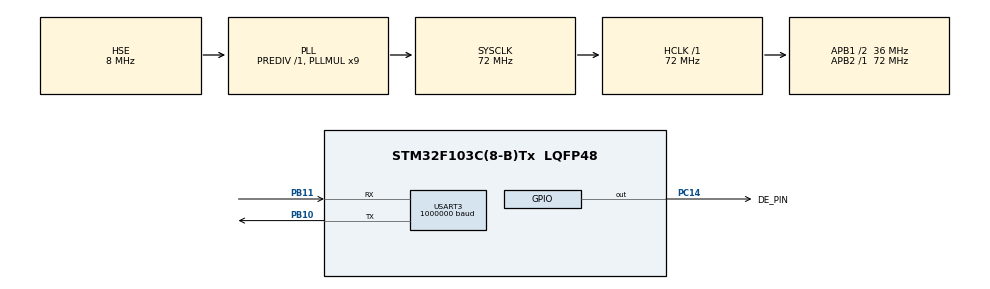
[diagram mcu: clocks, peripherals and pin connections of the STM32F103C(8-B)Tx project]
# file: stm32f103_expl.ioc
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FREERTOS.HEAP_NUMBER=4
FREERTOS.Tasks01=defaultTask,0,128,StartDefaultTask,Default,NULL
FREERTOS.configTOTAL_HEAP_SIZE=10000
Mcu.Family=STM32F1
Mcu.Name=STM32F103C(8-B)Tx
Mcu.Package=LQFP48
NVIC.PriorityGroup=NVIC_PRIORITYGROUP_4
NVIC.USART3_IRQn=true\:5\:0\:false\:false\:true\:true\:true\:true
PA13.Mode=JTAG_4_pins
PA13.Signal=SYS_JTMS-SWDIO
PA14.Mode=JTAG_4_pins
PA14.Signal=SYS_JTCK-SWCLK
PA15.Mode=JTAG_4_pins
PA15.Signal=SYS_JTDI
PB10.Mode=Asynchronous
PB10.Signal=USART3_TX
PB11.Mode=Asynchronous
PB11.Signal=USART3_RX
PB3.Mode=JTAG_4_pins
PB3.Signal=SYS_JTDO-TRACESWO
PC14-OSC32_IN.GPIO_Label=DE_PIN
PC14-OSC32_IN.Signal=GPIO_Output
PD0-OSC_IN.Mode=HSE-External-Oscillator
PD0-OSC_IN.Signal=RCC_OSC_IN
PD1-OSC_OUT.Mode=HSE-External-Oscillator
PD1-OSC_OUT.Signal=RCC_OSC_OUT
ProjectManager.HeapSize=0x200
ProjectManager.StackSize=0x400
ProjectManager.TargetToolchain=SW4STM32
RCC.AHBFreq_Value=72000000
RCC.APB1CLKDivider=RCC_HCLK_DIV2
RCC.APB1Freq_Value=36000000
RCC.APB1TimFreq_Value=72000000
RCC.APB2Freq_Value=72000000
RCC.APB2TimFreq_Value=72000000
RCC.HCLKFreq_Value=72000000
RCC.PLLMUL=RCC_PLL_MUL9
RCC.PLLSourceVirtual=RCC_PLLSOURCE_HSE
RCC.SYSCLKFreq_VALUE=72000000
RCC.SYSCLKSource=RCC_SYSCLKSOURCE_PLLCLK
RCC.USBFreq_Value=72000000
USART3.BaudRate=1000000
USART3.VirtualMode=VM_ASYNC
VP_FREERTOS_VS_CMSIS_V1.Mode=CMSIS_V1
board=custom

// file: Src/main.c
/* USER CODE BEGIN Header */
/**
  ******************************************************************************
  * @file           : main.c
  * @brief          : Main program body
  ******************************************************************************
  * @attention
  *
  * <h2><center>&copy; Copyright (c) 2019 STMicroelectronics.
  * All rights reserved.</center></h2>
  *
  * This software component is licensed by ST under BSD 3-Clause license,
  * the "License"; You may not use this file except in compliance with the
  * License. You may obtain a copy of the License at:
  *                        opensource.org/licenses/BSD-3-Clause
  *
  ******************************************************************************
  */
/* USER CODE END Header */

#include "main.h"
#include "cmsis_os.h"

/* USER CODE BEGIN Includes */
#include "ax12a.h"
/* USER CODE END Includes */

UART_HandleTypeDef huart3;

osThreadId defaultTaskHandle;

void SystemClock_Config(void);
static void MX_GPIO_Init(void);
static void MX_USART3_UART_Init(void);
void StartDefaultTask(void const * argument);

/* USER CODE BEGIN PFP */

uint8_t  packet[9];

int move(unsigned char ID, int Position) {
    char Position_H,Position_L;
    Position_H = Position >> 8;           // 16 bits - 2 x 8 bits variables
    Position_L = Position;

    const unsigned int length = 9;

    unsigned char Checksum = (~(ID + AX_GOAL_LENGTH + AX_WRITE_DATA + AX_GOAL_POSITION_L + Position_L + Position_H)) & 0xFF;

    packet[0] = AX_START;
    packet[1] = AX_START;
    packet[2] = ID;
    packet[3] = AX_GOAL_LENGTH;
    packet[4] = AX_WRITE_DATA;
    packet[5] = AX_GOAL_POSITION_L;
    packet[6] = Position_L;
    packet[7] = Position_H;
    packet[8] = Checksum;

    return HAL_UART_Transmit_IT(&huart3, packet, sizeof(packet));
}

unsigned char action_packet[6];
void action()
{
    const unsigned int length = 6;

    action_packet[0] = AX_START;
    action_packet[1] = AX_START;
    action_packet[2] = BROADCAST_ID;
    action_packet[3] = AX_ACTION_LENGTH;
    action_packet[4] = AX_ACTION;
    action_packet[5] = AX_ACTION_CHECKSUM;

    HAL_UART_Transmit_IT(&huart3, action_packet, length);
}
/* USER CODE END PFP */

int main(void)
{

  /* MCU Configuration--------------------------------------------------------*/

  /* Reset of all peripherals, Initializes the Flash interface and the Systick. */
  HAL_Init();

  /* Configure the system clock */
  SystemClock_Config();

  /* Initialize all configured peripherals */
  MX_GPIO_Init();
  MX_USART3_UART_Init();

  /* Create the thread(s) */
  /* definition and creation of defaultTask */
  osThreadDef(defaultTask, StartDefaultTask, osPriorityNormal, 0, 128);
  defaultTaskHandle = osThreadCreate(osThread(defaultTask), NULL);

  /* Start scheduler */
  osKernelStart();

  /* We should never get here as control is now taken by the scheduler */

  /* Infinite loop */
  /* USER CODE BEGIN WHILE */

    //uint8_t trasmit_buf[9] = {0xFF, 0xFF, 0x10, 0x05, 0x3, 0x1E, 0xB4, 0x0,0x15};
  while (1)
  {
    /* USER CODE END WHILE */

  }
}

void SystemClock_Config(void)
{
  RCC_OscInitTypeDef RCC_OscInitStruct = {0};
  RCC_ClkInitTypeDef RCC_ClkInitStruct = {0};

  /** Initializes the CPU, AHB and APB busses clocks
  */
  RCC_OscInitStruct.OscillatorType = RCC_OSCILLATORTYPE_HSE;
  RCC_OscInitStruct.HSEState = RCC_HSE_ON;
  RCC_OscInitStruct.HSEPredivValue = RCC_HSE_PREDIV_DIV1;
  RCC_OscInitStruct.HSIState = RCC_HSI_ON;
  RCC_OscInitStruct.PLL.PLLState = RCC_PLL_ON;
  RCC_OscInitStruct.PLL.PLLSource = RCC_PLLSOURCE_HSE;
  RCC_OscInitStruct.PLL.PLLMUL = RCC_PLL_MUL9;
  if (HAL_RCC_OscConfig(&RCC_OscInitStruct) != HAL_OK)
  {
    Error_Handler();
  }
  /** Initializes the CPU, AHB and APB busses clocks
  */
  RCC_ClkInitStruct.ClockType = RCC_CLOCKTYPE_HCLK|RCC_CLOCKTYPE_SYSCLK
                              |RCC_CLOCKTYPE_PCLK1|RCC_CLOCKTYPE_PCLK2;
  RCC_ClkInitStruct.SYSCLKSource = RCC_SYSCLKSOURCE_PLLCLK;
  RCC_ClkInitStruct.AHBCLKDivider = RCC_SYSCLK_DIV1;
  RCC_ClkInitStruct.APB1CLKDivider = RCC_HCLK_DIV2;
  RCC_ClkInitStruct.APB2CLKDivider = RCC_HCLK_DIV1;

  if (HAL_RCC_ClockConfig(&RCC_ClkInitStruct, FLASH_LATENCY_2) != HAL_OK)
  {
    Error_Handler();
  }
}

static void MX_USART3_UART_Init(void)
{

  huart3.Instance = USART3;
  huart3.Init.BaudRate = 1000000;
  huart3.Init.WordLength = UART_WORDLENGTH_8B;
  huart3.Init.StopBits = UART_STOPBITS_1;
  huart3.Init.Parity = UART_PARITY_NONE;
  huart3.Init.Mode = UART_MODE_TX_RX;
  huart3.Init.HwFlowCtl = UART_HWCONTROL_NONE;
  huart3.Init.OverSampling = UART_OVERSAMPLING_16;
  if (HAL_UART_Init(&huart3) != HAL_OK)
  {
    Error_Handler();
  }

}

static void MX_GPIO_Init(void)
{

  /* GPIO Ports Clock Enable */
  __HAL_RCC_GPIOD_CLK_ENABLE();
  __HAL_RCC_GPIOB_CLK_ENABLE();

}

void StartDefaultTask(void const * argument)
{

  for(;;)
  {
    osDelay(1);
  }
}

void Error_Handler(void)
{
}

/************************ (C) COPYRIGHT STMicroelectronics *****END OF FILE****/
